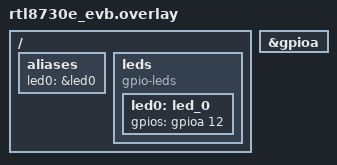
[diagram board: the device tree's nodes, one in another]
/*
 * Copyright (c) 2026 Realtek Semiconductor Corp.
 *
 * SPDX-License-Identifier: Apache-2.0
 */

/ {
	aliases {
		led0 = &led0;
	};

	leds {
		compatible = "gpio-leds";
		led0: led_0 {
			gpios = <&gpioa 12 GPIO_ACTIVE_HIGH>;
		};
	};
};

&gpioa {
	status = "okay";
};
